# ATmega644 device description
Architecture: AVR8; Family: megaAVR
Registers are 8-bit, access not given, no defined reset value unless marked. A register's access mark holds for its fields unless they carry their own. Offsets are from the block's base; [hi:lo] are bit positions.

## LOCKBIT — Lockbits
Instances: LOCKBIT 0 in lockbits
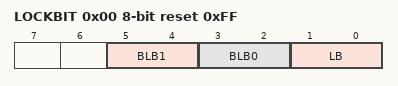
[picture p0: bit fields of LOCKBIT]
0x00 LOCKBIT reset 0xFF
  [5:4] BLB1 — Boot Loader Protection Mode
    0=LPM_SPM_DISABLE (LPM and SPM prohibited in Boot Section); 1=LPM_DISABLE (LPM prohibited in Boot Section); 2=SPM_DISABLE (SPM prohibited in Boot Section); 3=NO_LOCK (No lock on SPM and LPM in Boot Section)
  [3:2] BLB0 — Boot Loader Protection Mode
    0=LPM_SPM_DISABLE (LPM and SPM prohibited in Application Section); 1=LPM_DISABLE (LPM prohibited in Application Section); 2=SPM_DISABLE (SPM prohibited in Application Section); 3=NO_LOCK (No lock on SPM and LPM in Application Section)
  [1:0] LB — Memory Lock
    0=PROG_VER_DISABLED (Further programming and verification disabled); 2=PROG_DISABLED (Further programming disabled); 3=NO_LOCK (No memory lock features enabled)

## AC — Analog Comparator
Instances: AC 0x00
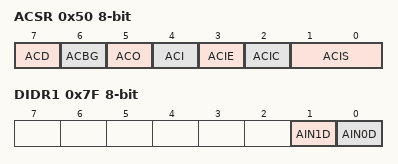
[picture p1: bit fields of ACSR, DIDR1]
0x50 ACSR — Analog Comparator Control And Status Register
  [7] ACD — Analog Comparator Disable
  [6] ACBG — Analog Comparator Bandgap Select
  [5] ACO — Analog Compare Output
  [4] ACI — Analog Comparator Interrupt Flag
  [3] ACIE — Analog Comparator Interrupt Enable
  [2] ACIC — Analog Comparator Input Capture Enable
  [1:0] ACIS — Analog Comparator Interrupt Mode Select bits
    0=Interrupt on Toggle; 2=Interrupt on Falling Edge; 3=Interrupt on Rising Edge
0x7B ADCSRB — ADC Control and Status Register B
  [6] ACME — Analog Comparator Multiplexer Enable
0x7F DIDR1 — Digital Input Disable Register 1
  [1] AIN1D — AIN1 Digital Input Disable
  [0] AIN0D — AIN0 Digital Input Disable

## USART0 — USART
Instances: USART0 0x00
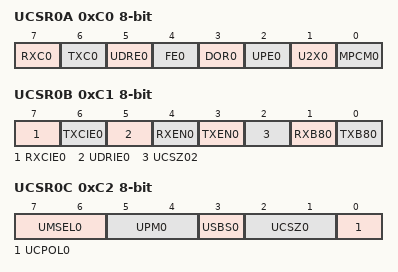
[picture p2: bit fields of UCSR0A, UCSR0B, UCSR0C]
0xC0 UCSR0A — USART Control and Status Register A
  [7] RXC0 — USART Receive Complete
  [6] TXC0 — USART Transmitt Complete
  [5] UDRE0 — USART Data Register Empty
  [4] FE0 — Framing Error
  [3] DOR0 — Data overRun
  [2] UPE0 — Parity Error
  [1] U2X0 — Double the USART transmission speed
  [0] MPCM0 — Multi-processor Communication Mode
0xC1 UCSR0B — USART Control and Status Register B
  [7] RXCIE0 — RX Complete Interrupt Enable
  [6] TXCIE0 — TX Complete Interrupt Enable
  [5] UDRIE0 — USART Data register Empty Interrupt Enable
  [4] RXEN0 — Receiver Enable
  [3] TXEN0 — Transmitter Enable
  [2] UCSZ02 — Character Size
  [1] RXB80 — Receive Data Bit 8
  [0] TXB80 — Transmit Data Bit 8
0xC2 UCSR0C — USART Control and Status Register C
  [7:6] UMSEL0 — USART Mode Select
    0=Asynchronous USART; 1=Synchronous USART; 3=Master SPI
  [5:4] UPM0 — Parity Mode Bits
    0=Disabled; 2=Enabled, Even Parity; 3=Enabled, Odd Parity
  [3] USBS0 — Stop Bit Select
    0=1-bit; 1=2-bit
  [2:1] UCSZ0 — Character Size
  [0] UCPOL0 — Clock Polarity
0xC4 UBRR0 16-bit bits used 11:0 — USART Baud Rate Register Bytes
0xC6 UDR0 — USART I/O Data Register

## PORTA — I/O Port
Instances: PORTA 0x00
0x20 PINA — Port A Input Pins
0x21 DDRA — Port A Data Direction Register
0x22 PORTA — Port A Data Register

## PORTB — I/O Port
Instances: PORTB 0x00
0x23 PINB — Port B Input Pins
0x24 DDRB — Port B Data Direction Register
0x25 PORTB — Port B Data Register

## PORTC — I/O Port
Instances: PORTC 0x00
0x26 PINC — Port C Input Pins
0x27 DDRC — Port C Data Direction Register
0x28 PORTC — Port C Data Register

## PORTD — I/O Port
Instances: PORTD 0x00
0x29 PIND — Port D Input Pins
0x2A DDRD — Port D Data Direction Register
0x2B PORTD — Port D Data Register

## TC0 (TC8 module) — Timer/Counter, 8-bit
Instances: TC0 0x00
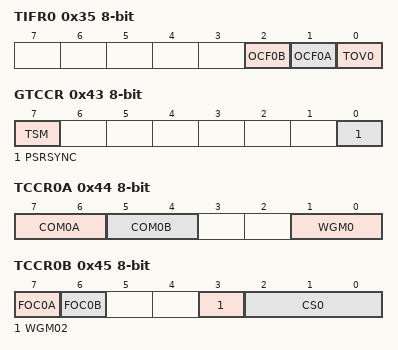
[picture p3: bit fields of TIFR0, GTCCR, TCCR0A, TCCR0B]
0x35 TIFR0 — Timer/Counter0 Interrupt Flag register
  [2] OCF0B — Timer/Counter0 Output Compare Flag 0B
  [1] OCF0A — Timer/Counter0 Output Compare Flag 0A
  [0] TOV0 — Timer/Counter0 Overflow Flag
0x43 GTCCR — General Timer/Counter Control Register
  [7] TSM — Timer/Counter Synchronization Mode
  [0] PSRSYNC — Prescaler Reset Timer/Counter1 and Timer/Counter0
0x44 TCCR0A — Timer/Counter Control Register A
  [7:6] COM0A — Compare Output Mode, Phase Correct PWM Mode
  [5:4] COM0B — Compare Output Mode, Fast PWm
  [1:0] WGM0 — Waveform Generation Mode
0x45 TCCR0B — Timer/Counter Control Register B
  [7] FOC0A — Force Output Compare A
  [6] FOC0B — Force Output Compare B
  [3] WGM02
  [2:0] CS0 — Clock Select
    0=No Clock Source (Stopped); 1=Running, No Prescaling; 2=Running, CLK/8; 3=Running, CLK/64; 4=Running, CLK/256; 5=Running, CLK/1024; 6=Running, ExtClk Tx Falling Edge; 7=Running, ExtClk Tx Rising Edge
0x46 TCNT0 — Timer/Counter0
0x47 OCR0A — Timer/Counter0 Output Compare Register
0x48 OCR0B — Timer/Counter0 Output Compare Register
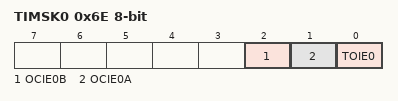
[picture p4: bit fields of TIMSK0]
0x6E TIMSK0 — Timer/Counter0 Interrupt Mask Register
  [2] OCIE0B — Timer/Counter0 Output Compare Match B Interrupt Enable
  [1] OCIE0A — Timer/Counter0 Output Compare Match A Interrupt Enable
  [0] TOIE0 — Timer/Counter0 Overflow Interrupt Enable
